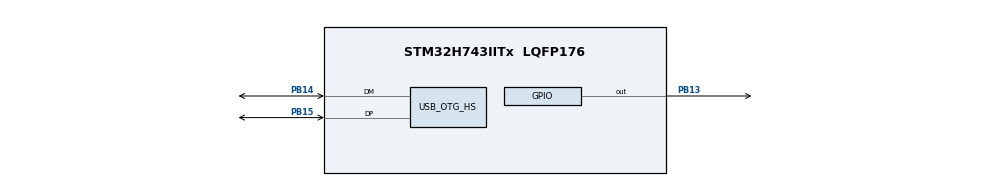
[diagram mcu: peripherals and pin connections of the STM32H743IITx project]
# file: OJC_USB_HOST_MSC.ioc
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FATFS._CODE_PAGE=936
FATFS._USE_LFN=2
Mcu.Family=STM32H7
Mcu.Name=STM32H743IITx
Mcu.Package=LQFP176
NVIC.OTG_HS_IRQn=true\:0\:0\:false\:false\:true\:false\:true
NVIC.PriorityGroup=NVIC_PRIORITYGROUP_4
PB13.PinState=GPIO_PIN_SET
PB13.Signal=GPIO_Output
PB14.Mode=Host_FS
PB14.Signal=USB_OTG_HS_DM
PB15.Mode=Host_FS
PB15.Signal=USB_OTG_HS_DP
PH0-OSC_IN\ (PH0).Mode=HSE-External-Oscillator
PH0-OSC_IN\ (PH0).Signal=RCC_OSC_IN
PH1-OSC_OUT\ (PH1).Mode=HSE-External-Oscillator
PH1-OSC_OUT\ (PH1).Signal=RCC_OSC_OUT
ProjectManager.HeapSize=0x1000
ProjectManager.StackSize=0x1000
ProjectManager.TargetToolchain=MDK-ARM V5.32
RCC.ADCFreq_Value=50390625
RCC.APB1Freq_Value=90000000
RCC.APB2Freq_Value=90000000
RCC.APB3Freq_Value=90000000
RCC.APB4Freq_Value=90000000
RCC.CortexFreq_Value=180000000
RCC.DIVM1=15
RCC.DIVN1=216
RCC.HCLKFreq_Value=90000000
RCC.HPRE=RCC_HCLK_DIV2
RCC.PLLSourceVirtual=RCC_PLLSOURCE_HSE
RCC.SYSCLKFreq_VALUE=180000000
RCC.SYSCLKSource=RCC_SYSCLKSOURCE_PLLCLK
RCC.USBCLockSelection=RCC_USBCLKSOURCE_HSI48
RCC.USBFreq_Value=48000000
USB_HOST.BSP.number=1
USB_HOST.USBH_HandleTypeDef-MSC_HS=hUsbHostHS
USB_HOST.VirtualModeHS=Msc
USB_HOST0.BSP.STBoard=false
USB_HOST0.BSP.api=Unknown
USB_HOST0.BSP.i2caddr=0
USB_HOST0.BSP.instance=PB13
USB_HOST0.BSP.ip=GPIO
USB_HOST0.BSP.mode=Output
USB_HOST0.BSP.name=Drive_VBUS_HS
USB_HOST0.BSP.solution=PB13
USB_OTG_HS.VirtualMode-Host_FS=Host_FS
VP_FATFS_VS_USB.Mode=USB
VP_USB_HOST_VS_USB_HOST_MSC_HS.Mode=MSC_HS
board=custom

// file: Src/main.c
/* USER CODE BEGIN Header */
/**
  ******************************************************************************
  * @file           : main.c
  * @brief          : Main program body
  ******************************************************************************
  * @attention
  *
  * Copyright (c) 2024 STMicroelectronics.
  * All rights reserved.
  *
  * This software is licensed under terms that can be found in the LICENSE file
  * in the root directory of this software component.
  * If no LICENSE file comes with this software, it is provided AS-IS.
  *
  ******************************************************************************
  */
/* USER CODE END Header */
#include "main.h"
#include "fatfs.h"
#include "usb_host.h"
#include "gpio.h"

void SystemClock_Config(void);
void MX_USB_HOST_Process(void);

/* USER CODE BEGIN 0 */
extern ApplicationTypeDef Appli_state;
extern USBH_HandleTypeDef hUsbHostFS;
extern char USBHPath[4]; // USBH logical drive path

FATFS FatfsUDisk; // File system object for USB disk logical drive
FIL myFile; // File object

static void MSC_Application(void)
{
    FRESULT fres; // FatFs function common result code
    uint32_t byteswrite;
    uint8_t str[] = "hello world!";

    /* Register the file system object to the FatFs module */
    if( f_mount(&FatfsUDisk, (TCHAR const*)USBHPath, 0) != FR_OK)
    {
        Error_Handler(); //FatFs Initialization Error
    }
    else
    {
        /* Create and Open a new text file object with write access */
        if(f_open(&myFile, "test.txt", FA_CREATE_ALWAYS | FA_WRITE) != FR_OK)
        {
            Error_Handler(); //'STM32.TXT' file Open for write Error
        }
        else
        {
            fres = f_write(&myFile, str, sizeof(str), (void *)&byteswrite);
            if(byteswrite == 0 || (fres != FR_OK))
            {
                Error_Handler();
            }
            else
            {
                f_close(&myFile); //Close the open text file
            }
        }
    }
}
/* USER CODE END 0 */

int main(void)
{

  /* MCU Configuration--------------------------------------------------------*/

  /* Reset of all peripherals, Initializes the Flash interface and the Systick. */
  HAL_Init();

  /* Configure the system clock */
  SystemClock_Config();

  /* Initialize all configured peripherals */
  MX_GPIO_Init();
  MX_FATFS_Init();
  MX_USB_HOST_Init();

  /* Infinite loop */
  while (1)
  {
    MX_USB_HOST_Process();

    /* USER CODE BEGIN 3 */
		switch(Appli_state)
    {
        case APPLICATION_READY:
            MSC_Application();
            Appli_state = APPLICATION_DISCONNECT;
            break;
        case APPLICATION_DISCONNECT:
            f_mount(NULL, "", 0);
            break;
        default:
            break;
    }
  }
  /* USER CODE END 3 */
}

void SystemClock_Config(void)
{
  RCC_OscInitTypeDef RCC_OscInitStruct = {0};
  RCC_ClkInitTypeDef RCC_ClkInitStruct = {0};

  /** Supply configuration update enable
  */
  HAL_PWREx_ConfigSupply(PWR_LDO_SUPPLY);
  /** Configure the main internal regulator output voltage
  */
  __HAL_PWR_VOLTAGESCALING_CONFIG(PWR_REGULATOR_VOLTAGE_SCALE3);

  while(!__HAL_PWR_GET_FLAG(PWR_FLAG_VOSRDY)) {}
  /** Initializes the RCC Oscillators according to the specified parameters
  * in the RCC_OscInitTypeDef structure.
  */
  RCC_OscInitStruct.OscillatorType = RCC_OSCILLATORTYPE_HSI48|RCC_OSCILLATORTYPE_HSE;
  RCC_OscInitStruct.HSEState = RCC_HSE_ON;
  RCC_OscInitStruct.HSI48State = RCC_HSI48_ON;
  RCC_OscInitStruct.PLL.PLLState = RCC_PLL_ON;
  RCC_OscInitStruct.PLL.PLLSource = RCC_PLLSOURCE_HSE;
  RCC_OscInitStruct.PLL.PLLM = 15;
  RCC_OscInitStruct.PLL.PLLN = 216;
  RCC_OscInitStruct.PLL.PLLP = 2;
  RCC_OscInitStruct.PLL.PLLQ = 2;
  RCC_OscInitStruct.PLL.PLLR = 2;
  RCC_OscInitStruct.PLL.PLLRGE = RCC_PLL1VCIRANGE_0;
  RCC_OscInitStruct.PLL.PLLVCOSEL = RCC_PLL1VCOWIDE;
  RCC_OscInitStruct.PLL.PLLFRACN = 0;
  if (HAL_RCC_OscConfig(&RCC_OscInitStruct) != HAL_OK)
  {
    Error_Handler();
  }
  /** Initializes the CPU, AHB and APB buses clocks
  */
  RCC_ClkInitStruct.ClockType = RCC_CLOCKTYPE_HCLK|RCC_CLOCKTYPE_SYSCLK
                              |RCC_CLOCKTYPE_PCLK1|RCC_CLOCKTYPE_PCLK2
                              |RCC_CLOCKTYPE_D3PCLK1|RCC_CLOCKTYPE_D1PCLK1;
  RCC_ClkInitStruct.SYSCLKSource = RCC_SYSCLKSOURCE_PLLCLK;
  RCC_ClkInitStruct.SYSCLKDivider = RCC_SYSCLK_DIV1;
  RCC_ClkInitStruct.AHBCLKDivider = RCC_HCLK_DIV2;
  RCC_ClkInitStruct.APB3CLKDivider = RCC_APB3_DIV1;
  RCC_ClkInitStruct.APB1CLKDivider = RCC_APB1_DIV1;
  RCC_ClkInitStruct.APB2CLKDivider = RCC_APB2_DIV1;
  RCC_ClkInitStruct.APB4CLKDivider = RCC_APB4_DIV1;

  if (HAL_RCC_ClockConfig(&RCC_ClkInitStruct, FLASH_LATENCY_1) != HAL_OK)
  {
    Error_Handler();
  }
}

void Error_Handler(void)
{
  __disable_irq();
  while (1)
  {
  }
}
